# ExynosT100 register map
Vendor: SAMSUNG System LSI; Series: ARMCM4F; File version: 0.1
CPU: CM4 r1p0, little endian, MPU, FPU, 3 interrupt priority bits
Registers are 32-bit, read-write, reset 0x0 unless marked. A register's access mark holds for its fields unless they carry their own. Offsets are from the block's base; [hi:lo] are bit positions; {n}, {i} and the like mark numbered series; <NAME> marks a mode.

## USIB
Base 0x40020000
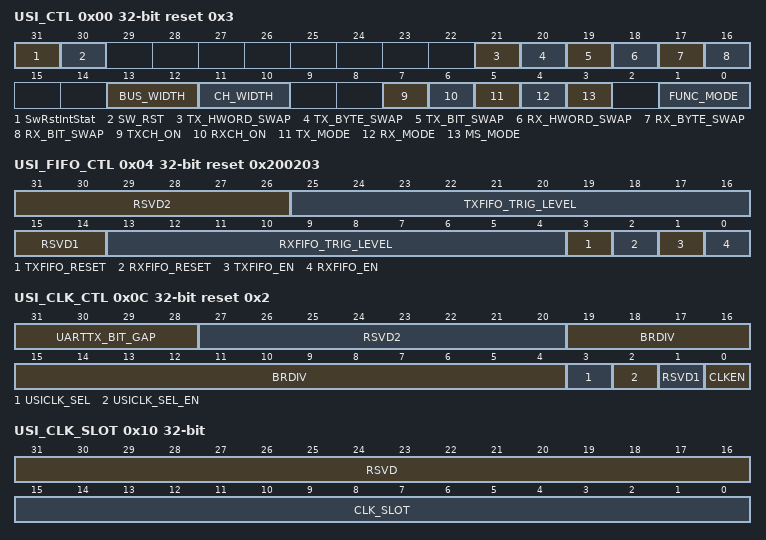
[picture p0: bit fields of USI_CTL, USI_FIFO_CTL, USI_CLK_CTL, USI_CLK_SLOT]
0x00 USI_CTL reset 0x3 — USI Control Register
  [31] SwRstIntStat — Indicates software reset signal This bit clears the Rx/Tx FIFO data and USI_STATUS registers and bits. 0 = Inactive 1 = Active NOTE: This bit cannot clear automatically when set by writing a 1. So you should release this bit by writing a 0
  [30] SW_RST — Indicates software reset signal This bit clears USI_STATUS. 0 = Inactive S/W reset 1 = Active S/W reset NOTE: This bit cannot clear automatically when set by writing a 1. So you should release this bit by writing a 0
  [21] TX_HWORD_SWAP — Turn on or turn off half-word swap operation on Tx channel 0 = Off 1 = On
  [20] TX_BYTE_SWAP — Turn on or turn off byte swap operation on Tx channel 0 = Off 1 = On
  [19] TX_BIT_SWAP — Turn on or turn off bit swap operation on Tx channel 0 = Off 1 = On
  [18] RX_HWORD_SWAP — Turn on or turn off half-word swap operation on Rx channel 0 = Off 1 = On
  [17] RX_BYTE_SWAP — Turn on or turn off byte swap operation on Rx channel 0 = Off 1 = On
  [16] RX_BIT_SWAP — Turn on or turn off bit swap operation on Rx channel 0 = Off 1 = On
  [13:12] BUS_WIDTH — 00 = Byte 01 = Half-word 10 = Word 11 = Reserved
  [11:10] CH_WIDTH — 00 = Byte 01 = Half-word 10 = Word 11 = Reserved NOTE: This bit should be set to 00 for I2C and UART functions.
  [7] TXCH_ON — Specifies the Tx channel enable signal 0 = Disable 1 = Enable NOTE: TXCHON must be set after all configuration is completed, that is, configuration cannot be set after Tx channels start working.
  [6] RXCH_ON — Specifies the Rx channel enable signal 0 = Disable 1 = Enable NOTE: RXCHON must be set after all configuration is completed, that is, configuration cannot be set after Rx channels start working.
  [5] TX_MODE — Determines the function used to read data from transmit buffer register 0 = Interrupt 1 = DMA
  [4] RX_MODE — Determines the function used to write data into receive buffer register 0 = Interrupt 1 = DMA
  [3] MS_MODE — Determines whether USI is master or slave 0 = Slave 1 = Master
  [1:0] FUNC_MODE — Specifies the function mode bits 00 = SPI function 01 = I2C function 10 = UART function 11 = Reserved
0x04 USI_FIFO_CTL reset 0x200203 — USI FIFO Control Register
  [31:26] RSVD2 ro
  [25:16] TXFIFO_TRIG_LEVEL — Specifies the trigger level to generate TXFIFO_ALMOST_EMPTY interrupt If the byte number in Tx FIFO is less than the trigger level, the TXFIFO_ALMOST_EMPTY interrupt is generated. NOTE: The trigger level is used for interrupt. The maximum value is 272.
  [15:14] RSVD1 ro
  [13:4] RXFIFO_TRIG_LEVEL — Specifies the trigger level to generate RXFIFO_ALMOST_FULL interrupt If the byte number in Rx FIFO is more than the trigger level, the RXFIFO_ALMOST_FULL interrupt is generated. NOTE: The trigger level is used for interrupt. The maximum value is 272.
  [3] TXFIFO_RESET — Specifies Tx FIFO reset for FIFO flush This is not released automatically. 0 = No effect 1 = Reset
  [2] RXFIFO_RESET — Specifies Rx FIFO reset for FIFO flush This is not released automatically. 0 = No effect 1 = Reset
  [1] TXFIFO_EN — Specifies the Tx FIFO enable signal 0 = Disable (FIFO-depth = 1 byte) 1 = Enable (FIFO-depth = 64 bytes)
  [0] RXFIFO_EN — Specifies the Rx FIFO enable signal 0 = Disable (FIFO-depth = 1 byte) 1 = Enable (FIFO-depth = 64 bytes)
0x0C USI_CLK_CTL reset 0x2 — USI Clock Control Register
  [31:28] UARTTX_BIT_GAP — UART Tx sampling type selection For 16 sampling, set this field as 0x0 For 8 sampling, set this field as 0x8
  [27:20] RSVD2 ro
  [19:4] BRDIV — Specifies the baud rate division value
  [3] USICLK_SEL — USI clock source selection 0 = HCLKsys 1 = USICLK NOTE: If USICLK_SEL_EN = 0, then this value is ignored.
  [2] USICLK_SEL_EN — USI clock source selection enable 0 = USICLK (for UART mode) or HCLKsys (for SPI and I2C modes) 1 = Determined by USICLK_SEL bit (HCLK sys or USICLK)
  [1] RSVD1
  [0] CLKEN
0x10 USI_CLK_SLOT — USI Clock Slot Register for Non-Integer Divider
  [31:16] RSVD ro
  [15:0] CLK_SLOT — Selects the slot where clock generator divides clock source To see Table 14 2 and Table 14 3 NOTE: In case of 8 sampling, USI_CLK_SLOT uses 8-LSB only
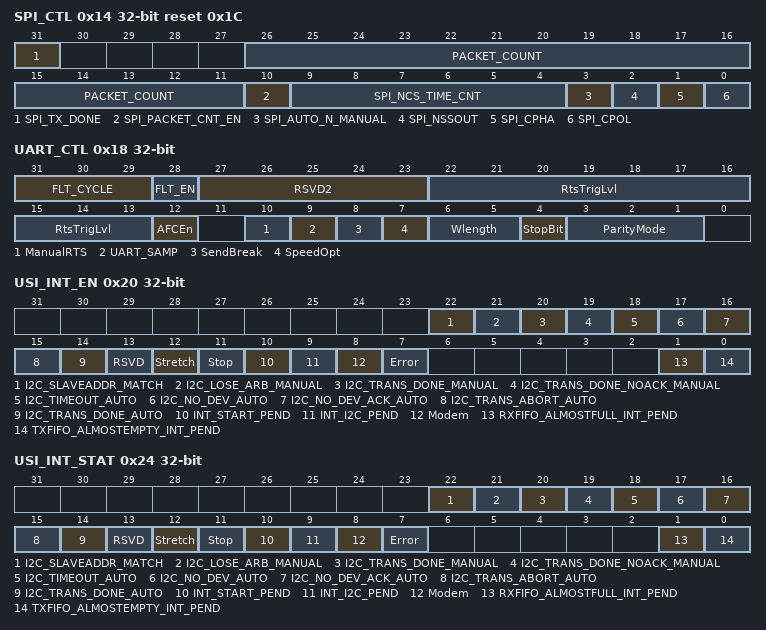
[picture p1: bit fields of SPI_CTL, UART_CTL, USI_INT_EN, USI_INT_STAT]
0x14 SPI_CTL reset 0x1C — Special Control Register for SPI Function
  [31] SPI_TX_DONE ro — Indicates transfer done in shift register in master mode 0 = Tx FIFO or shift register is not empty 1 = Tx FIFO and shift register are empty
  [26:11] PACKET_COUNT — Specifies the packet count number
  [10] SPI_PACKET_CNT_EN — Enables signal for packet counting in master mode 0 = Disable 1 = Enable
  [9:4] SPI_NCS_TIME_CNT — Specifies the nSS inactive time period NSSOUT inactive time = nCS_time_count * SPICLKout
  [3] SPI_AUTO_N_MANUAL — Specifies the auto nSS control or manual nSS control 1 = Auto 0 = Manual
  [2] SPI_NSSOUT — Slave selection signal (manual) 0 = Active 1 = Inactive
  [1] SPI_CPHA — Selects one of the two fundamentally different transfer formats 0 = Format A 1 = Format B
  [0] SPI_CPOL — Determines an active high or active low clock 0 = Active high 1 = Active low
0x18 UART_CTL — UART Control Register
  [31:29] FLT_CYCLE — RXD/CTS signal filter cycle selection
  [28] FLT_EN — RXD/CTS signal filter enable
  [27:23] RSVD2
  [22:13] RtsTrigLvl — When AFCEN bit is set, these bits determine when to inactive nRTS signal. RxFFLvl < RtsTrigLvl NOTE: These bits are used only for UART AFC mode.
  [12] AFCEn — Enable signal for auto flow control 0 = Disable 1 = Enable
  [10] ManualRTS — If AFCEN bit is enabled, this value is ignored. In this case, the chip controls nRTS automatically If AFCEN bit is disabled, nRTS must be controlled by software. 0 = H level (Inactive nRTS) 1 = L level (Active nRTS)
  [9] UART_SAMP ro — 0 = 16 sampling 1 = 8 sampling
  [8] SendBreak — Setting this bit causes UART to send a break signal during 1 frame time This bit is auto-cleared after detecting the break-send request. 0 = Normal transmit 1 = Sends break signal
  [7] SpeedOpt — UART speed option 0 = Disables 1 = Enables(Ignore Stop bit)
  [6:5] Wlength — ndicates the number of data bits to be transmitted or received per frame 00 = 5-bit 01 = 6-bit 10 = 7-bit 11 = 8-bit
  [4] StopBit — Specifies how many stop bits are used for end-of-frame signal 0 = One stop bit per frame 1 = Two stop bits per frame
  [3:1] ParityMode — Specify the parity type during transmit and receive operation 0xx = No parity 100 = Odd parity 101 = Even parity 110 = Parity forced/checked as 1 111 = Parity forced/checked as 0
0x20 USI_INT_EN — USI Interrupt Enable Register
  [22] I2C_SLAVEADDR_MATCH — Interrupt pending signal for interface start Write 1 to clear this bit. 0 = No interrupt 1 = Interrupt W1C
  [21] I2C_LOSE_ARB_MANUAL — Interrupt pending signal for interface start Write 1 to clear this bit. 0 = No interrupt 1 = Interrupt W1C
  [20] I2C_TRANS_DONE_MANUAL — Interrupt pending signal for interface start Write 1 to clear this bit. 0 = No interrupt 1 = Interrupt W1C
  [19] I2C_TRANS_DONE_NOACK_MANUAL — Interrupt pending signal for interface start Write 1 to clear this bit. 0 = No interrupt 1 = Interrupt W1C
  [18] I2C_TIMEOUT_AUTO — Interrupt pending signal for interface start Write 1 to clear this bit. 0 = No interrupt 1 = Interrupt W1C
  [17] I2C_NO_DEV_AUTO — Interrupt pending signal for interface start Write 1 to clear this bit. 0 = No interrupt 1 = Interrupt W1C
  [16] I2C_NO_DEV_ACK_AUTO — Interrupt pending signal for interface start Write 1 to clear this bit. 0 = No interrupt 1 = Interrupt W1C
  [15] I2C_TRANS_ABORT_AUTO — Interrupt pending signal for interface start Write 1 to clear this bit. 0 = No interrupt 1 = Interrupt W1C
  [14] I2C_TRANS_DONE_AUTO — Interrupt pending signal for I2C Write 1 to clear this bit. 0 = No interrupt 1 = Interrupt
  [13] RSVD — Interrupt pending signal for I2C Write 1 to clear this bit. 0 = No interrupt 1 = Interrupt
  [12] Stretch — Interrupt pending signal for I2C Write 1 to clear this bit. 0 = No interrupt 1 = Interrupt
  [11] Stop — Interrupt pending signal for I2C Write 1 to clear this bit. 0 = No interrupt 1 = Interrupt
  [10] INT_START_PEND — Interrupt pending signal for I2C Write 1 to clear this bit. 0 = No interrupt 1 = Interrupt
  [9] INT_I2C_PEND — Interrupt pending signal for I2C Write 1 to clear this bit. 0 = No interrupt 1 = Interrupt
  [8] Modem — Write 1 to clear this bit Read 0 = No-interrupt 1 = Interrupt occurs
  [7] Error — Write 1 to clear this bit Read: If an error occurs, this bit is set to 1 0 = No error occurred 1 = Error occurred
  [1] RXFIFO_ALMOSTFULL_INT_PEND — Interrupt pending signal for Rx FIFO almost full Write 1 to clear this bit. READ: 0 = Data in Rx FIFO is less than trigger level 1 = Data in Rx FIFO is more than trigger level
  [0] TXFIFO_ALMOSTEMPTY_INT_PEND — Interrupt pending signal for Tx FIFO almost empty Write 1 to clear this bit. READ: 0 = Data in Tx FIFO is more than trigger level 1 = Data in Tx FIFO is less than trigger level
0x24 USI_INT_STAT — USI Interrupt Register
  [22] I2C_SLAVEADDR_MATCH rw-once — Interrupt pending signal for interface start Write 1 to clear this bit. 0 = No interrupt 1 = Interrupt W1C
  [21] I2C_LOSE_ARB_MANUAL rw-once — Interrupt pending signal for interface start Write 1 to clear this bit. 0 = No interrupt 1 = Interrupt W1C
  [20] I2C_TRANS_DONE_MANUAL rw-once — Interrupt pending signal for interface start Write 1 to clear this bit. 0 = No interrupt 1 = Interrupt W1C
  [19] I2C_TRANS_DONE_NOACK_MANUAL rw-once — Interrupt pending signal for interface start Write 1 to clear this bit. 0 = No interrupt 1 = Interrupt W1C
  [18] I2C_TIMEOUT_AUTO rw-once — Interrupt pending signal for interface start Write 1 to clear this bit. 0 = No interrupt 1 = Interrupt W1C
  [17] I2C_NO_DEV_AUTO rw-once — Interrupt pending signal for interface start Write 1 to clear this bit. 0 = No interrupt 1 = Interrupt W1C
  [16] I2C_NO_DEV_ACK_AUTO rw-once — Interrupt pending signal for interface start Write 1 to clear this bit. 0 = No interrupt 1 = Interrupt W1C
  [15] I2C_TRANS_ABORT_AUTO rw-once — Interrupt pending signal for interface start Write 1 to clear this bit. 0 = No interrupt 1 = Interrupt W1C
  [14] I2C_TRANS_DONE_AUTO rw-once — Interrupt pending signal for I2C Write 1 to clear this bit. 0 = No interrupt 1 = Interrupt
  [13] RSVD rw-once — Interrupt pending signal for I2C Write 1 to clear this bit. 0 = No interrupt 1 = Interrupt
  [12] Stretch rw-once — Interrupt pending signal for I2C Write 1 to clear this bit. 0 = No interrupt 1 = Interrupt
  [11] Stop rw-once — Interrupt pending signal for I2C Write 1 to clear this bit. 0 = No interrupt 1 = Interrupt
  [10] INT_START_PEND rw-once — Interrupt pending signal for I2C Write 1 to clear this bit. 0 = No interrupt 1 = Interrupt
  [9] INT_I2C_PEND rw-once — Interrupt pending signal for I2C Write 1 to clear this bit. 0 = No interrupt 1 = Interrupt
  [8] Modem rw-once — Write 1 to clear this bit Read 0 = No-interrupt 1 = Interrupt occurs
  [7] Error rw-once — Write 1 to clear this bit Read: If an error occurs, this bit is set to 1 0 = No error occurred 1 = Error occurred
  [1] RXFIFO_ALMOSTFULL_INT_PEND ro — Interrupt pending signal for Rx FIFO almost full Write 1 to clear this bit. READ: 0 = Data in Rx FIFO is less than trigger level 1 = Data in Rx FIFO is more than trigger level
  [0] TXFIFO_ALMOSTEMPTY_INT_PEND ro — Interrupt pending signal for Tx FIFO almost empty Write 1 to clear this bit. READ: 0 = Data in Tx FIFO is more than trigger level 1 = Data in Tx FIFO is less than trigger level
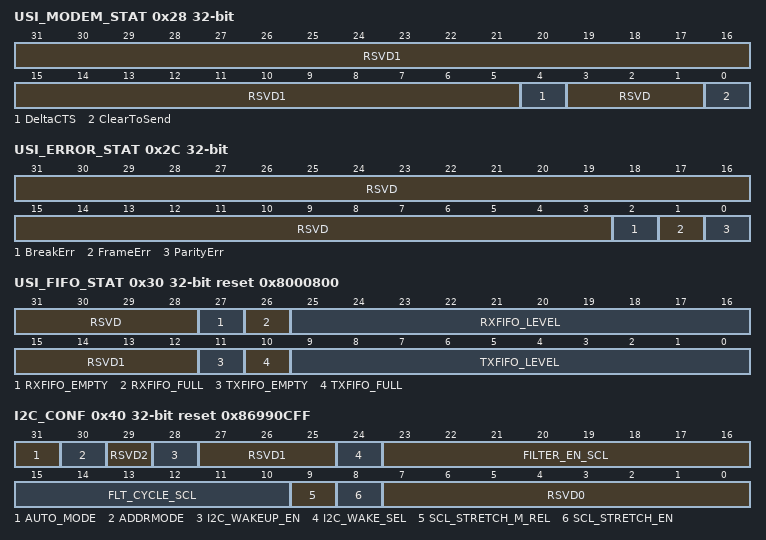
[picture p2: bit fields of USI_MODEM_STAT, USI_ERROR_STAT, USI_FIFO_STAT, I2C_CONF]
0x28 USI_MODEM_STAT ro — USI FIFO Status Register
  [31:5] RSVD1
  [4] DeltaCTS — Break error for byte0
  [3:1] RSVD — Frame error for byte0 0 = No frame error occurred 1 = Frame error occurred
  [0] ClearToSend — Parity error for byte0 0 = No parity error occurred 1 = Parity error occurred
0x2C USI_ERROR_STAT ro — USI FIFO Status Register
  [31:3] RSVD
  [2] BreakErr — Break error for byte0
  [1] FrameErr — Frame error for byte0 0 = No frame error occurred 1 = Frame error occurred
  [0] ParityErr — Parity error for byte0 0 = No parity error occurred 1 = Parity error occurred
0x30 USI_FIFO_STAT ro reset 0x8000800 — USI FIFO Status Register
  [31:28] RSVD
  [27] RXFIFO_EMPTY — Rx FIFO empty signal 0 = Non-empty 1 = Empty
  [26] RXFIFO_FULL — Rx FIFO full signal 0 = Non-full 1 = Full
  [25:16] RXFIFO_LEVEL — Data level in Rx FIFO
  [15:12] RSVD1
  [11] TXFIFO_EMPTY — Tx FIFO empty signal 0 = Non-empty 1 = Empty
  [10] TXFIFO_FULL — Tx FIFO full signal 0 = Non-full 1 = Full
  [9:0] TXFIFO_LEVEL — Data level in Tx FIFO
0x34 USI_TXDATA wo reset 0xDEADBEAF — USI Transmitted Data Buffer Register
  [31:0] TXFIFO_WDATA — Transmit data buffer for USI
0x38 USI_RXDATA ro — USI Received Data Buffer Register
  [31:0] RXFIFO_RDATA — Received data buffer for USI
0x40 I2C_CONF reset 0x86990CFF — I2C Configuration
  [31] AUTO_MODE — Auto flow control for I2C master 1 = Auto control. I2C master automatically controls the whole transaction. 0 = Manual control. Software manually controls transaction.
  [30] ADDRMODE — Selection of I2C interface address mode 1 = 10-bit address mode 0 = 7-bit address mode
  [29] RSVD2 ro — Need to be Zero
  [28] I2C_WAKEUP_EN — I2C Wakeup source generation enable 0 = Disable 1 = Enable After I2C address matching compare, wakeup signal is generated.
  [27:25] RSVD1 ro
  [24] I2C_WAKE_SEL — Wake-up type selection 0 = Address matching type 1 = Start monitor type
  [23:16] FILTER_EN_SCL — SCL signal filter enable
  [15:10] FLT_CYCLE_SCL
  [9] SCL_STRETCH_M_REL — I2C stretch release bit, when I2C stretch is used as manual mode I2C_CONF[27] is stretch type selection bit. 0 = Auto 1 = Manual When you set this bit to manual and StretchEn bit is enabled, then set this bit to 1 every time to release the I2C stretch function. If SCL_STRETCH_EN is enabled, manual stretch can be controlled.
  [8] SCL_STRETCH_EN — I2C stretch mode enable 0 = Stretch disable 1 = I2C stretch mode enable
  [7:0] RSVD0 ro
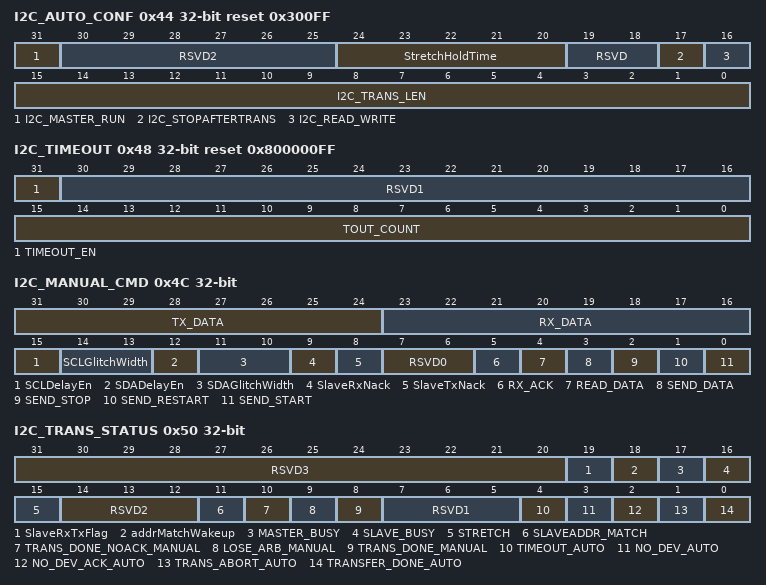
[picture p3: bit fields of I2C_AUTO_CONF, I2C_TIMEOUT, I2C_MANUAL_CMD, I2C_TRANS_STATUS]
0x44 I2C_AUTO_CONF reset 0x300FF — I2C Configuration for Auto Mode
  [31] I2C_MASTER_RUN wo — I2C run signal for master mode To start data transfer under I2C master mode, write 1 to this bit.
  [30:25] RSVD2 ro
  [24:20] StretchHoldTime — Need to control by S/W Stretch release time after FIFO control. The time is (STR_HOLD_TIME)x(EXT_CLK) This is only applicable for slave mode.
  [19:18] RSVD
  [17] I2C_STOPAFTERTRANS — For auto_mode only. If this bit is set, i2c master asserts stop condition after entire transaction is complete, either success or failure.
  [16] I2C_READ_WRITE — Type of transaction For AUTO_MODE only. 0 = Write (Tx) 1 = Read (Rx)
  [15:0] I2C_TRANS_LEN — Length of transaction (number of bytes to Rx or Tx)
0x48 I2C_TIMEOUT reset 0x800000FF — Time Out for I2C Master
  [31] TIMEOUT_EN — Enables timing out
  [30:16] RSVD1 ro
  [15:0] TOUT_COUNT — Timing out for master Rx/Tx
0x4C I2C_MANUAL_CMD — Command Register for Manual Mode
  [31:24] TX_DATA — Specifies the data to be transmitted
  [23:16] RX_DATA ro
  [15] SCLDelayEn — SCL signal delay filter enable 0 = Disable 1 = Enable
  [14:13] SCLGlitchWidth ro — SCL glitch width to be removed 00 = rsvd 01 = rsvd 10 = 50 ns 11 = 60 ns
  [12] SDADelayEn — SCL signal delay filter enable 0 = Disable 1 = Enable
  [11:10] SDAGlitchWidth — 0 = No effect 1 = When address match
  [9] SlaveRxNack — 0 = No effect 1 = When address match
  [8] SlaveTxNack — 0 = No effect 1 = Stretch release manually
  [7:6] RSVD0
  [5] RX_ACK
  [4] READ_DATA wo
  [3] SEND_DATA wo
  [2] SEND_STOP wo
  [1] SEND_RESTART wo
  [0] SEND_START wo
0x50 I2C_TRANS_STATUS — I2C Transfer Status
  [31:20] RSVD3 ro
  [19] SlaveRxTxFlag ro — On slave busy, read/write state monitoring flag when slave is busy
  [18] addrMatchWakeup ro — address match wakeup flag(from i2c_wakeup module)
  [17] MASTER_BUSY ro — Indicates whether the data is transferring or not in master mode 1 = The data is transferring 2 = The data is not transferring
  [16] SLAVE_BUSY ro — Indicates whether the data is transferring or not in slave mode 1 = The data is transferring 2 = The data is not transferring
  [15] STRETCH ro — Indicates clock stretch in slave mode 0 = N/A 1 = Clock stretching
  [14:12] RSVD2 ro
  [11] SLAVEADDR_MATCH ro — I2C slave address is matched For slave mode only (I2C interrupt source).
  [10] TRANS_DONE_NOACK_MANUAL ro — Transfer completed without ACK received For manual mode only. NOTE: After master ID (HS mode), this bit should be asserted (I2C interrupt source).
  [9] LOSE_ARB_MANUAL ro — Lost arbitration during executing command For manual mode only (I2C interrupt source).
  [8] TRANS_DONE_MANUAL ro — One byte (data or address) is transmitted successfully, one byte (data) is received successfully, or command (start or stop) is completed For manual mode only (I2C interrupt source). Note: In HS mode, completion of master ID transfer does not assert this bit.
  [7:5] RSVD1 ro
  [4] TIMEOUT_AUTO ro — Time out during auto mode transaction
  [3] NO_DEV_AUTO ro — No device responds to the address No device is selected by master. For auto mode only (I2C interrupt source).
  [2] NO_DEV_ACK_AUTO ro — Device does not return ACK during master transmission For auto mode only (I2C interrupt source).
  [1] TRANS_ABORT_AUTO ro — Lost arbitration during transaction For auto mode only (I2C interrupt source).
  [0] TRANSFER_DONE_AUTO ro — Command is executed successfully This bit is automatically cleared by software read. For auto mode only (I2C interrupt source).
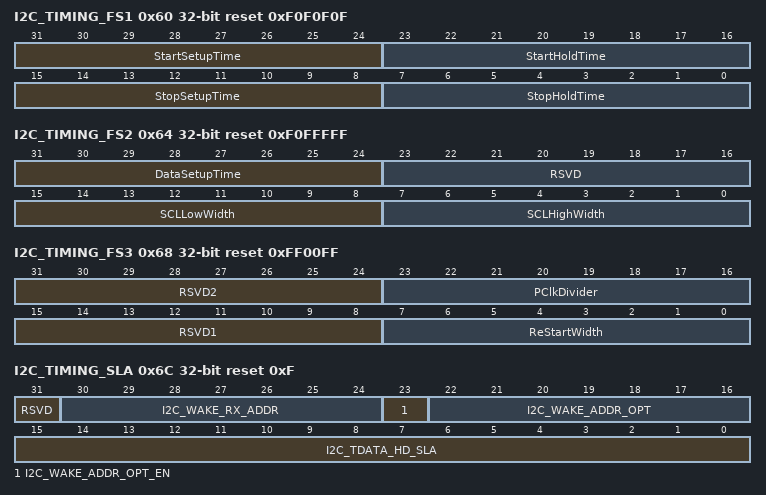
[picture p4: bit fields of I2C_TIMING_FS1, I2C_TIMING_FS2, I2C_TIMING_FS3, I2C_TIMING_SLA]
0x60 I2C_TIMING_FS1 reset 0xF0F0F0F — TimTiming Parameter for Fast-Speed Mode
  [31:24] StartSetupTime — Start condition setup timing (Start condition after SCL rising-edge)
  [23:16] StartHoldTime — Start condition hold timing (Start condition leads to SCL falling-edge)
  [15:8] StopSetupTime — STOP condition setup timing.(Stop condition after SCL rising-edge)
  [7:0] StopHoldTime — Stop condition hold timing.(Stop condition leads to SCL falling-edge)
0x64 I2C_TIMING_FS2 reset 0xF0FFFFF — Timing Parameter for Fast-Speed Mode
  [31:24] DataSetupTime — Data setup timing
  [23:16] RSVD
  [15:8] SCLLowWidth — SCL low Period
  [7:0] SCLHighWidth — SCL high period
0x68 I2C_TIMING_FS3 reset 0xFF00FF — Timing Parameter for Fast-Speed Mode
  [31:24] RSVD2 ro
  [23:16] PClkDivider — The SYSCLK divider factor when working in FS-mode
  [15:8] RSVD1 ro
  [7:0] ReStartWidth — Re-start condition
0x6C I2C_TIMING_SLA reset 0xF — Timing Parameter for I2C Slave
  [31] RSVD ro, [30:24] I2C_WAKE_RX_ADDR ro, [23] I2C_WAKE_ADDR_OPT_EN, [22:16] I2C_WAKE_ADDR_OPT, [15:0] I2C_TDATA_HD_SLA
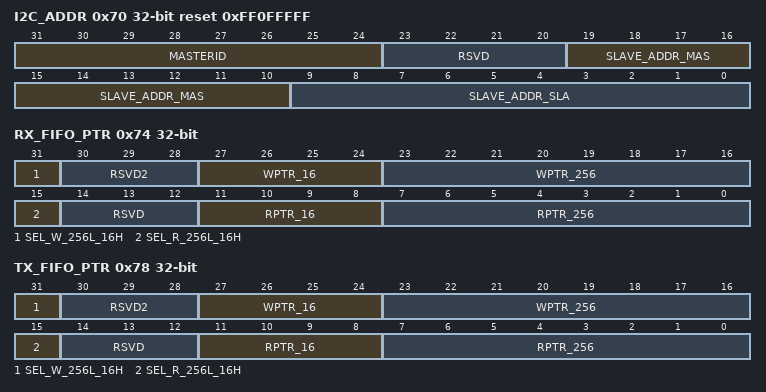
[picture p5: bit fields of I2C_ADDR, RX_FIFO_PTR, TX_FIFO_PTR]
0x70 I2C_ADDR reset 0xFF0FFFFF — Address Register I2C slave address I2C master ID Slave address for master
  [31:24] MASTERID — Master ID for I2C master For auto mode and HS mode only
  [23:20] RSVD ro
  [19:10] SLAVE_ADDR_MAS — Slave address for I2C master For auto mode only.
  [9:0] SLAVE_ADDR_SLA — Slave address for I2C slave
0x74 RX_FIFO_PTR ro — Rx FIFO Pointer Registe
  [31] SEL_W_256L_16H — Write pointer selection 0 = 256 FIFO selection 1 = 16 FIFO selection
  [30:28] RSVD2
  [27:24] WPTR_16 — Rx 16 FIFO write pointer
  [23:16] WPTR_256 — Rx 256 FIFO write pointer
  [15] SEL_R_256L_16H — Read pointer selection 0 = 256 FIFO selection 1 = 16 FIFO selection
  [14:12] RSVD
  [11:8] RPTR_16 — Rx 16 FIFO read pointer
  [7:0] RPTR_256 — Rx 256 FIFO read pointer
0x78 TX_FIFO_PTR ro — Tx FIFO Pointer Register
  [31] SEL_W_256L_16H — Write pointer selection 0 = 256 FIFO selection 1 = 16 FIFO selection
  [30:28] RSVD2
  [27:24] WPTR_16 — Tx 16 FIFO write pointer
  [23:16] WPTR_256 — Tx 256 FIFO write pointer
  [15] SEL_R_256L_16H — Read pointer selection 0 = 256 FIFO selection 1 = 16 FIFO selection
  [14:12] RSVD
  [11:8] RPTR_16 — Tx 16 FIFO read pointer
  [7:0] RPTR_256 — Tx 256 FIFO read pointer

## I2CB0
Base 0x40021000
Same registers: I2CB1 0x40021400
Registers as USIB, without USI_CLK_SLOT, SPI_CTL, USI_MODEM_STAT, USI_ERROR_STAT, RX_FIFO_PTR, TX_FIFO_PTR.

## UART0
Base 0x40022000
Same registers: UART1 0x40022400
Registers as USIB, without SPI_CTL, USI_MODEM_STAT, I2C_CONF, I2C_AUTO_CONF, I2C_TIMEOUT, I2C_MANUAL_CMD, I2C_TRANS_STATUS, I2C_TIMING_FS{n} (n=1..3), I2C_TIMING_SLA, I2C_ADDR, RX_FIFO_PTR, TX_FIFO_PTR.
